# STM32F101C4T6 register map
File version: 1.0
Registers are 32-bit, access not given, reset 0x0 unless marked. A register's access mark holds for its fields unless they carry their own. Offsets are from the block's base; [hi:lo] are bit positions; {n}, {i} and the like mark numbered series.

## USBFS
Base 0x40005C00
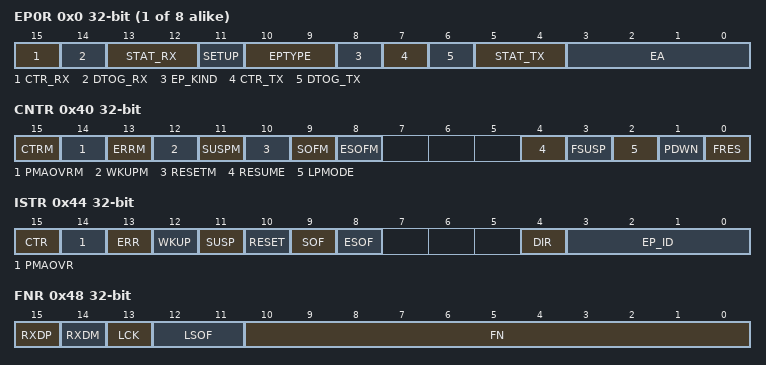
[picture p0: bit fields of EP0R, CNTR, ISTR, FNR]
{0x0+4i} EP{i}R (i=0..7)
  [15] CTR_RX, [14] DTOG_RX, [13:12] STAT_RX, [11] SETUP, [10:9] EPTYPE, [8] EP_KIND, [7] CTR_TX, [6] DTOG_TX, [5:4] STAT_TX, [3:0] EA
0x40 CNTR
  [15] CTRM, [14] PMAOVRM, [13] ERRM, [12] WKUPM, [11] SUSPM, [10] RESETM, [9] SOFM, [8] ESOFM, [4] RESUME, [3] FSUSP, [2] LPMODE, [1] PDWN, [0] FRES
0x44 ISTR
  [15] CTR, [14] PMAOVR, [13] ERR, [12] WKUP, [11] SUSP, [10] RESET, [9] SOF, [8] ESOF, [4] DIR, [3:0] EP_ID
0x48 FNR
  [15] RXDP, [14] RXDM, [13] LCK, [12:11] LSOF, [10:0] FN
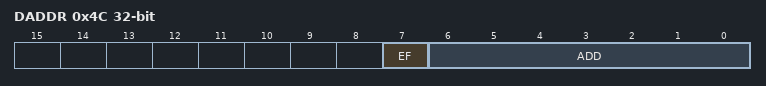
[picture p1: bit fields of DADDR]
0x4C DADDR
  [7] EF, [6:0] ADD
0x50 BTABLE
  [15:3] BTABLE

## CAN1
Base 0x40006400
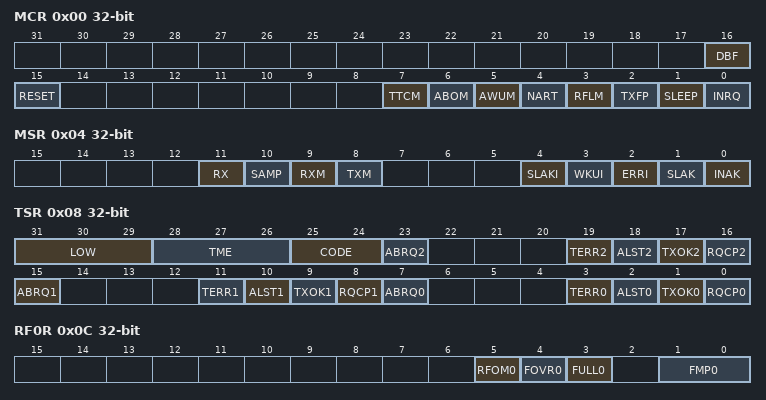
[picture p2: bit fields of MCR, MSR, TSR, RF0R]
0x00 MCR
  [16] DBF, [15] RESET, [7] TTCM, [6] ABOM, [5] AWUM, [4] NART, [3] RFLM, [2] TXFP, [1] SLEEP, [0] INRQ
0x04 MSR
  [11] RX, [10] SAMP, [9] RXM, [8] TXM, [4] SLAKI, [3] WKUI, [2] ERRI, [1] SLAK, [0] INAK
0x08 TSR
  [31:29] LOW, [28:26] TME, [25:24] CODE, [23] ABRQ2, [19] TERR2, [18] ALST2, [17] TXOK2, [16] RQCP2, [15] ABRQ1, [11] TERR1, [10] ALST1, [9] TXOK1, [8] RQCP1, [7] ABRQ0, [3] TERR0, [2] ALST0, [1] TXOK0, [0] RQCP0
0x0C RF0R
  [5] RFOM0, [4] FOVR0, [3] FULL0, [1:0] FMP0
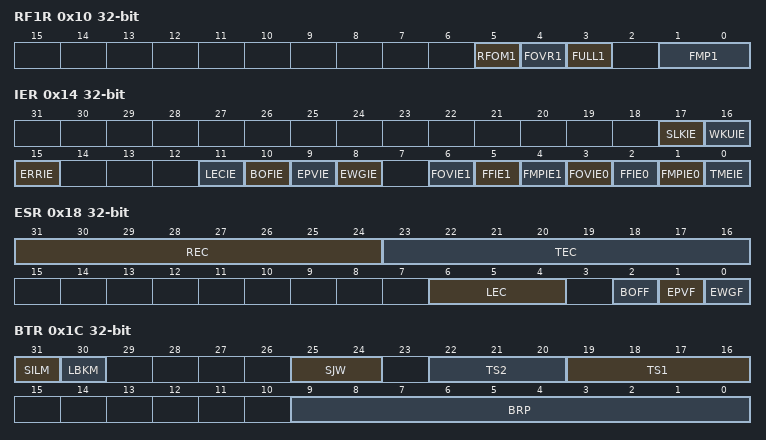
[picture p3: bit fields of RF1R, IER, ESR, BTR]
0x10 RF1R
  [5] RFOM1, [4] FOVR1, [3] FULL1, [1:0] FMP1
0x14 IER
  [17] SLKIE, [16] WKUIE, [15] ERRIE, [11] LECIE, [10] BOFIE, [9] EPVIE, [8] EWGIE, [6] FOVIE1, [5] FFIE1, [4] FMPIE1, [3] FOVIE0, [2] FFIE0, [1] FMPIE0, [0] TMEIE
0x18 ESR
  [31:24] REC, [23:16] TEC, [6:4] LEC, [2] BOFF, [1] EPVF, [0] EWGF
0x1C BTR
  [31] SILM, [30] LBKM, [25:24] SJW, [22:20] TS2, [19:16] TS1, [9:0] BRP
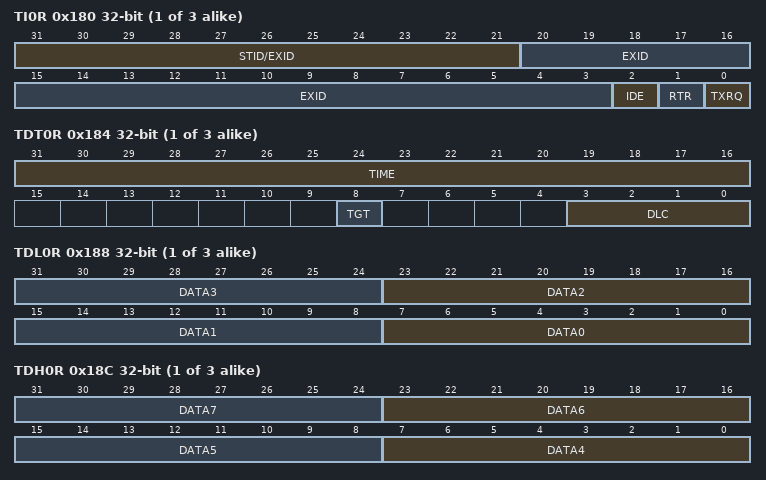
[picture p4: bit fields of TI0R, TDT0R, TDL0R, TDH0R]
{0x180+0x10*i} TI{i}R (i=0..2)
  [31:21] STID/EXID, [20:3] EXID, [2] IDE, [1] RTR, [0] TXRQ
{0x184+0x10*i} TDT{i}R (i=0..2)
  [31:16] TIME, [8] TGT, [3:0] DLC
{0x188+0x10*i} TDL{i}R (i=0..2)
  [8n+7:8n] DATA{n} (n=0..3)
{0x18C+0x10*i} TDH{i}R (i=0..2)
  [8n-25:8n-32] DATA{n} (n=4..7)
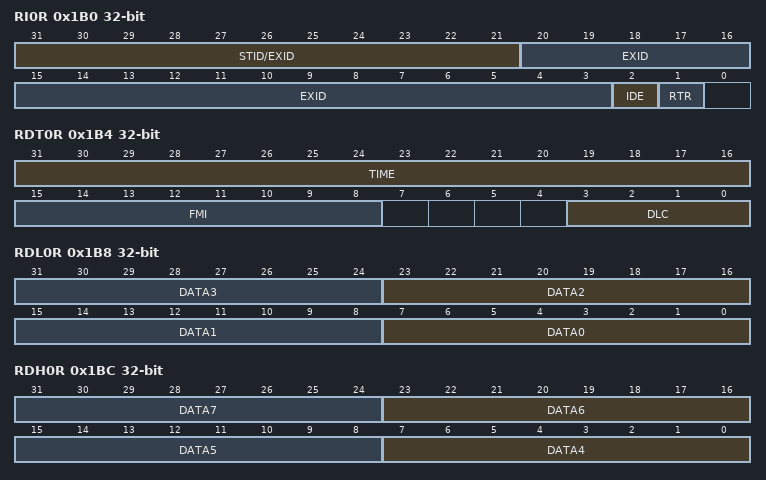
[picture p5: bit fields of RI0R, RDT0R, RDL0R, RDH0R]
0x1B0 RI0R
  [31:21] STID/EXID, [20:3] EXID, [2] IDE, [1] RTR
0x1B4 RDT0R
  [31:16] TIME, [15:8] FMI, [3:0] DLC
0x1B8 RDL0R
  [8n+7:8n] DATA{n} (n=0..3)
0x1BC RDH0R
  [8n-25:8n-32] DATA{n} (n=4..7)
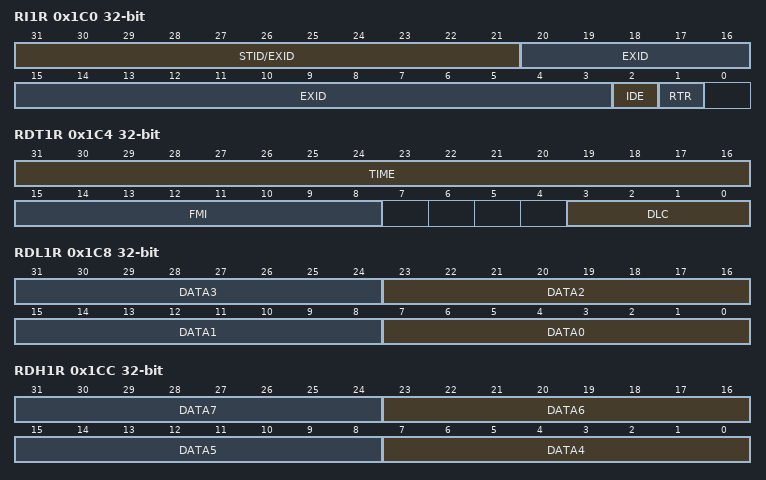
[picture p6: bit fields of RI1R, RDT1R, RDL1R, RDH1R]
0x1C0 RI1R
  [31:21] STID/EXID, [20:3] EXID, [2] IDE, [1] RTR
0x1C4 RDT1R
  [31:16] TIME, [15:8] FMI, [3:0] DLC
0x1C8 RDL1R
  [8n+7:8n] DATA{n} (n=0..3)
0x1CC RDH1R
  [8n-25:8n-32] DATA{n} (n=4..7)
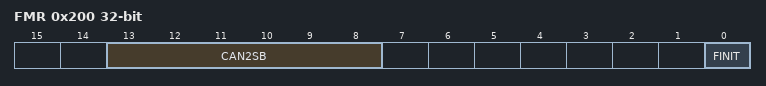
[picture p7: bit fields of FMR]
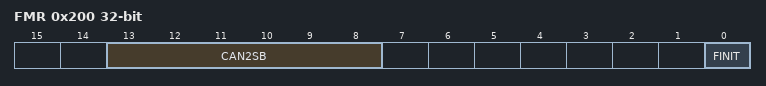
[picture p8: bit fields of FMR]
0x200 FMR
  [13:8] CAN2SB, [0] FINIT
0x204 FM1R
  [27:0] FBM
0x20C FS1R
  [27:0] FSC
0x214 FFA1R
  [27:0] FFA
0x21C FA1R
  [27:0] FACT
{0x240+8i} F{i}R1 (i=0..27)
  [31:0] FB
{0x244+8i} F{i}R2 (i=0..27)
  [31:0] FB

## CAN2
Base 0x40006800
Registers as CAN1; these are added or differ:
0x200 FMR
  [13:8] CAN2SB, [0] FINIT

## BKP
Base 0x40006C00
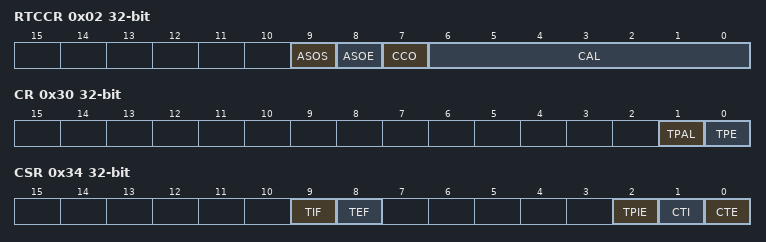
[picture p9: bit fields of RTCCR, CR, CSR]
0x02 RTCCR
  [9] ASOS, [8] ASOE, [7] CCO, [6:0] CAL
{0x0+4i} DR{i} (i=1..10)
  [15:0] D
0x30 CR
  [1] TPAL, [0] TPE
0x34 CSR
  [9] TIF, [8] TEF, [2] TPIE, [1] CTI, [0] CTE
{0x14+4i} DR{i} (i=11..42)
  [15:0] D

## PWR
Base 0x40007000
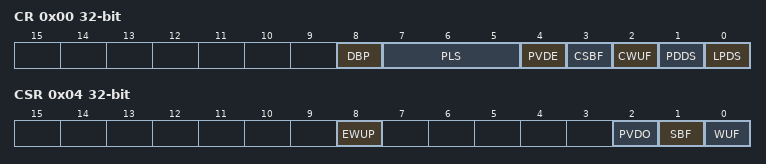
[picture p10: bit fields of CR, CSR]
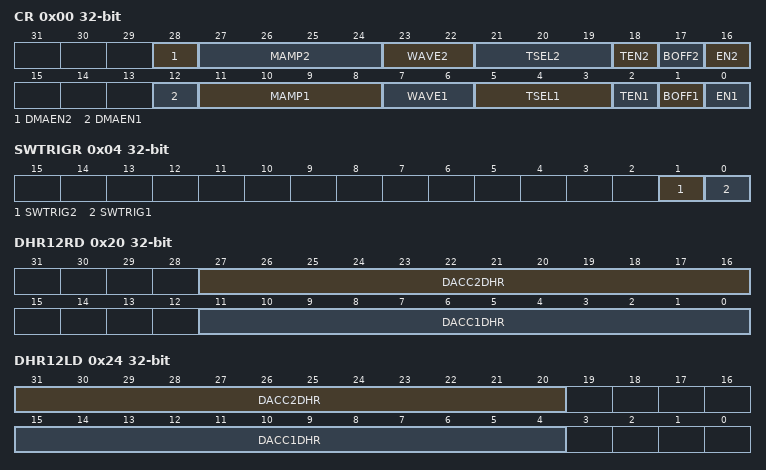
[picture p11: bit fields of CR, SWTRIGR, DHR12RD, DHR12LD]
0x00 CR
  [8] DBP, [7:5] PLS, [4] PVDE, [3] CSBF, [2] CWUF, [1] PDDS, [0] LPDS
0x04 CSR
  [8] EWUP, [2] PVDO, [1] SBF, [0] WUF

## DAC
Base 0x40007400
0x00 CR
  [28] DMAEN2, [27:24] MAMP2, [23:22] WAVE2, [21:19] TSEL2, [18] TEN2, [17] BOFF2, [16] EN2, [12] DMAEN1, [11:8] MAMP1, [7:6] WAVE1, [5:3] TSEL1, [2] TEN1, [1] BOFF1, [0] EN1
0x04 SWTRIGR
  [1] SWTRIG2, [0] SWTRIG1
0x08 DHR12R1
  [11:0] DACC1DHR
0x0C DHR12L1
  [15:4] DACC1DHR
0x10 DHR8R1
  [7:0] DACC1DHR
0x14 DHR12R2
  [11:0] DACC2DHR
0x18 DHR12L2
  [15:4] DACC2DHR
0x1C DHR8R2
  [7:0] DACC2DHR
0x20 DHR12RD
  [27:16] DACC2DHR, [11:0] DACC1DHR
0x24 DHR12LD
  [31:20] DACC2DHR, [15:4] DACC1DHR
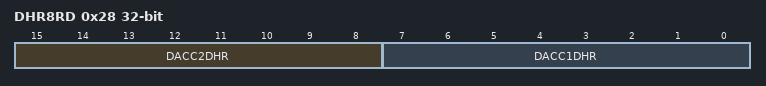
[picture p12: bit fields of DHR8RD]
0x28 DHR8RD
  [15:8] DACC2DHR, [7:0] DACC1DHR
0x2C DOR1
  [11:0] DACC1DOR
0x30 DOR2
  [11:0] DACC2DOR

## AFIO
Base 0x40010000
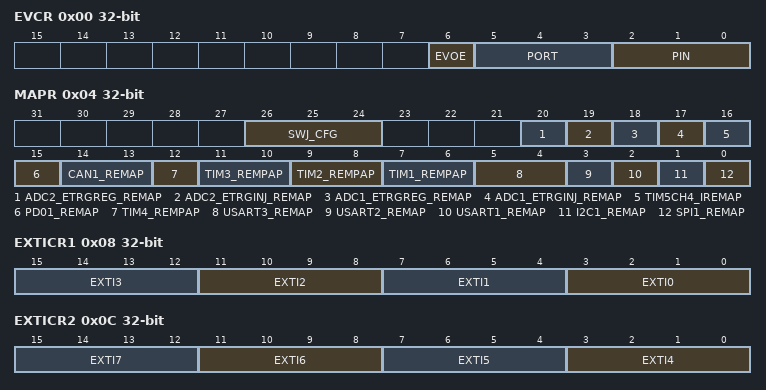
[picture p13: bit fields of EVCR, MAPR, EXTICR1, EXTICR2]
0x00 EVCR
  [6] EVOE, [5:3] PORT, [2:0] PIN
0x04 MAPR
  [26:24] SWJ_CFG, [20] ADC2_ETRGREG_REMAP, [19] ADC2_ETRGINJ_REMAP, [18] ADC1_ETRGREG_REMAP, [17] ADC1_ETRGINJ_REMAP, [16] TIM5CH4_IREMAP, [15] PD01_REMAP, [14:13] CAN1_REMAP, [12] TIM4_REMPAP, [11:10] TIM3_REMPAP, [9:8] TIM2_REMPAP, [7:6] TIM1_REMPAP, [5:4] USART3_REMAP, [3] USART2_REMAP, [2] USART1_REMAP, [1] I2C1_REMAP, [0] SPI1_REMAP
0x08 EXTICR1
  [4n+3:4n] EXTI{n} (n=0..3)
0x0C EXTICR2
  [4n-13:4n-16] EXTI{n} (n=4..7)
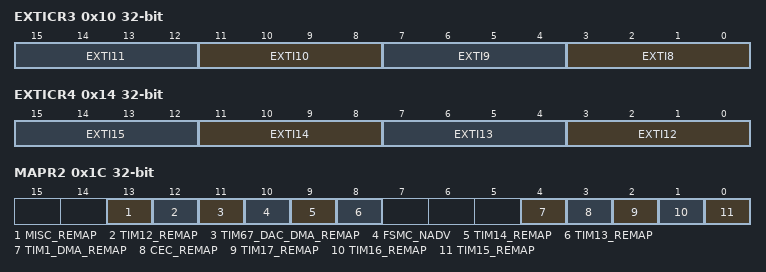
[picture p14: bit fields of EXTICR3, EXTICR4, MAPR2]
0x10 EXTICR3
  [4n-29:4n-32] EXTI{n} (n=8..11)
0x14 EXTICR4
  [4n-45:4n-48] EXTI{n} (n=12..15)
0x1C MAPR2
  [13] MISC_REMAP, [12] TIM12_REMAP, [11] TIM67_DAC_DMA_REMAP, [10] FSMC_NADV, [9] TIM14_REMAP, [8] TIM13_REMAP, [4] TIM1_DMA_REMAP, [3] CEC_REMAP, [2] TIM17_REMAP, [1] TIM16_REMAP, [0] TIM15_REMAP
